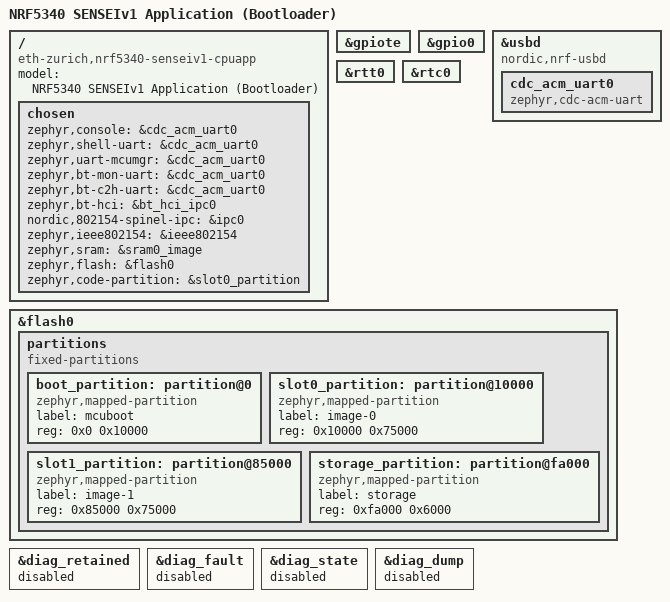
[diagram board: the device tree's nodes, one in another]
// Copyright (c) 2025 ETH Zurich and University of Bologna
// SPDX-License-Identifier: Apache-2.0

/dts-v1/;
#include <nordic/nrf5340_cpuapp_qkaa.dtsi>
#include <zephyr/dt-bindings/input/input-event-codes.h>

/ {
	model = "NRF5340 SENSEIv1 Application (Bootloader)";
	compatible = "eth-zurich,nrf5340-senseiv1-cpuapp";

	chosen {
		zephyr,console = &cdc_acm_uart0;
		zephyr,shell-uart = &cdc_acm_uart0;
		zephyr,uart-mcumgr = &cdc_acm_uart0;
		zephyr,bt-mon-uart = &cdc_acm_uart0;
		zephyr,bt-c2h-uart = &cdc_acm_uart0;
		zephyr,bt-hci = &bt_hci_ipc0;
		nordic,802154-spinel-ipc = &ipc0;
		zephyr,ieee802154 = &ieee802154;
		zephyr,sram = &sram0_image;
		zephyr,flash = &flash0;
		zephyr,code-partition = &slot0_partition;
	};

};

#include "nrf5340_senseiv1_shared.dtsi"

&gpiote {
	status = "okay";
};

&gpio0 {
	status = "okay";
};

zephyr_udc0: &usbd {
	compatible = "nordic,nrf-usbd";
	status = "okay";
	cdc_acm_uart0: cdc_acm_uart0 {
			compatible = "zephyr,cdc-acm-uart";
	};
};


&rtt0 {
    status = "okay";
};

&rtc0 {
	status = "okay";
};


&flash0 {
	partitions {
		compatible = "fixed-partitions";
		#address-cells = <1>;
		#size-cells = <1>;
		ranges;

		/* Swap using move needs no scratch area: the two image slots take the space up to the storage. */
		boot_partition: partition@0 {
			compatible = "zephyr,mapped-partition";
			label = "mcuboot";
			reg = <0x0 0x10000>;
		};
		slot0_partition: partition@10000 {
			compatible = "zephyr,mapped-partition";
			label = "image-0";
			reg = <0x10000 0x75000>;
		};
		slot1_partition: partition@85000 {
			compatible = "zephyr,mapped-partition";
			label = "image-1";
			reg = <0x85000 0x75000>;
		};
		storage_partition: partition@fa000 {
			compatible = "zephyr,mapped-partition";
			label = "storage";
			reg = <0xfa000 0x6000>;
		};
	};
};

/* RAM plan (256 kB secure, 192 kB non-secure application, 64 kB shared with the network core). */
#include <nordic/nrf5340_sram_partition.dtsi>
#include <nordic/nrf5340_shared_sram_partition.dtsi>

/* The same RAM plan as the application: MCUboot must not touch the retained RAM. Boot mode for serial recovery. */
#include "nrf5340_senseiv1_retained.dtsi"

/* MCUboot only needs the boot mode (GPREGRET1): no drivers for the diagnostics areas (saves about 0.5 kB).
 *
 * This file is used only when the board is named with the variant (nrf5340_senseiv1/nrf5340/cpuapp/bootloader). The
 * sysbuild of the node builds MCUboot for the plain cpuapp board (nrf5340_senseiv1/nrf5340/cpuapp), so there the
 * diagnostics areas stay enabled and cost about 0.5 kB (RETAINED_MEM_ZEPHYR_RAM). To drop them there, the app's
 * sysbuild/mcuboot.overlay (sysbuild picks it up by name) disables the same four nodes:
 *
 *   &diag_retained { status = "disabled"; };
 *   &diag_fault { status = "disabled"; };
 *   &diag_state { status = "disabled"; };
 *   &diag_dump { status = "disabled"; };
 */
&diag_retained {
	status = "disabled";
};
&diag_fault {
	status = "disabled";
};
&diag_state {
	status = "disabled";
};
&diag_dump {
	status = "disabled";
};
